# YTM32B1MC0 register map
Vendor: YTMicro; File version: 1.0
CPU: CM33 r0p4, little endian, MPU, FPU, 2 interrupt priority bits
Registers are 32-bit, read-write, reset 0x0 unless marked. A register's access mark holds for its fields unless they carry their own. Offsets are from the block's base; [hi:lo] are bit positions; {n}, {i} and the like mark numbered series; 'fields as' and 'values as' point back to an identical list.

## HCU — Hardware Cryptography Unit
Base 0x40067000; register names take the prefix HCU_
0x00 GO
  [0] GO — Start Encryption/Decryption and indicate the module work state, write 0 to this bit is invalid.
    0=Encryption/Decryption idle; 1=Encryption/Decryption running
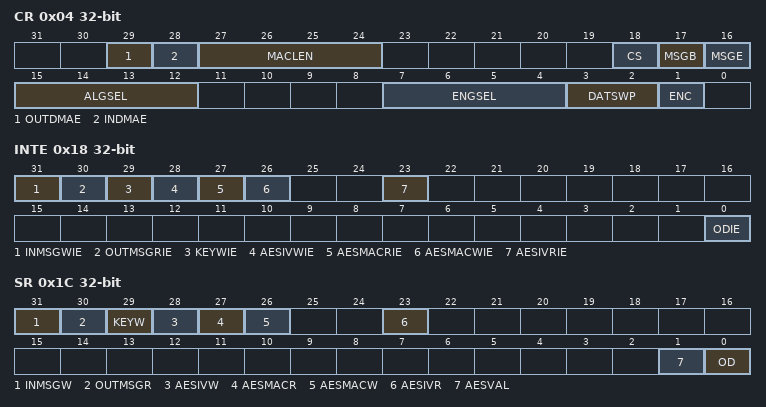
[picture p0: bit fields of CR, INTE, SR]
0x04 CR
  [29] OUTDMAE — Output message DMA enable/disable.
    0=Output message DMA is disabled; 1=Output message DMA is enabled
  [28] INDMAE — Input message DMA enable/disable.
    0=Input message dma is disabled; 1=Input message dma is enabled
  [27:24] MACLEN — MAC length for generation or validation.
    0=16 bytes; 1=1 byte; {v}={v} bytes (v=2..15)
  [18] CS — Store the context data, for multiple message blocks process.
    0=Don't store context data; 1=Store context data
  [17] MSGB — Indicate the first message block, for multiple message blocks process.
    0=Current data block isn't the first block of the whole data; 1=Current data block is the first block of the whole data
  [16] MSGE — Indicate the last message block, for multiple message blocks process.
    0=Current data block isn't the last block of the whole data; 1=Current data block is the last block of the whole data
  [15:12] ALGSEL — Select algorithm for selected engine.
    0=AES-ECB; 1=AES-CBC; 4=AES-CMAC
  [7:4] ENGSEL — Select engine for encryption/decryption.
    0=disable; 1=AES
  [3:2] DATSWP — Select the type of data swapping.
    0=No swapping; 1=Half-word swapping; 2=Byte swapping; 3=Bit swapping
  [1] ENC — Select encryption or decryption mode.
    0=Decryption; 1=Encryption
0x0C MSGCUR
  [15:0] MSGLEN — Indicate byte number of message in current block.
0x18 INTE
  [31] INMSGWIE — Input message wait interrupt enable/disable.
    0=Input message wait interrupt disable; 1=Input message wait interrupt enable
  [30] OUTMSGRIE — Output message ready interrupt enable/disable.
    0=Output message ready interrupt disable; 1=Output message ready interrupt enable
  [29] KEYWIE — Key wait interrupt enable/disable.
    0=Key wait interrupt disable; 1=Key wait interrupt enable
  [28] AESIVWIE — AES initial vector wait interrupt enable/disable.
    0=AES initial vector wait interrupt disable; 1=AES initial vector wait interrupt enable
  [27] AESMACRIE — AES MAC ready interrupt enable/disable.
    0=AES MAC ready interrupt disable; 1=AES MAC ready interrupt enable
  [26] AESMACWIE — AES MAC wait interrupt enable/disable.
    0=AES MAC wait interrupt disable; 1=AES MAC wait interrupt enable
  [23] AESIVRIE — AES initial vector ready interrupt enable/disable.
    0=AES initial vector ready interrupt disable; 1=AES initial vector ready interrupt enable
  [0] ODIE — Operation done interrupt enable/disable.
    0=Operation done interrupt disable; 1=Operation done interrupt enable
0x1C SR
  [31] INMSGW ro — Input message wait flag.
    0=Don't care; 1=HCU is waiting for input message. Need write INMSG register.
  [30] OUTMSGR ro — Output message ready flag.
    0=Don't care; 1=Output message is ready for reading. Need read OUTMSG register.
  [29] KEYW ro — Key wait flag.
    0=Don't care; 1=HCU is waiting for key. Need write KEY registers or execute load key value EFM command.
  [28] AESIVW ro — AES initial vector wait flag.
    0=Don't care; 1=HCU is waiting for AES initial vector. Need write CONTEXT_4_7 registers.
  [27] AESMACR ro — AES MAC ready flag.
    0=Don't care; 1=AES MAC is ready for reading. Need read CONTEXT_8_11 registers.
  [26] AESMACW ro — AES MAC wait flag.
    0=Don't care; 1=HCU is waiting for AES MAC. Need write CONTEXT_8_11 registers.
  [23] AESIVR ro — AES initial vector ready flag.
    0=Don't care; 1=AES initial vector is ready for reading. Need read CONTEXT_4_7 registers.
  [1] AESVAL ro — Indicate AES MAC validation result.
    0=The input MAC is not equal to the calculate result; 1=The input MAC is equal to the calculate result
  [0] OD — Indicate Encryption/Decryption operation state. Write 1 to clear this bit.
    0=Operation doesn't begin or under running; 1=Operation done
{0x20+4i} KEY{i} wo (i=0..3)
  [31:0] KEY rw — Key value for Encryption/Decryption.
0x60 CONTEXT_4_70
  [31:0] CONTEXT — Initial vector value for AES Encryption/Decryption.
0x64 CONTEXT_4_71
  [31:0] CONTEXT — Initial vector value for AES Encryption/Decryption.
0x68 CONTEXT_4_72
  [31:0] CONTEXT — Initial vector value for AES Encryption/Decryption.
0x6C CONTEXT_4_73
  [31:0] CONTEXT — Initial vector value for AES Encryption/Decryption.
0x70 CONTEXT_8_110
  [31:0] CONTEXT — MAC value generated in AES Encryption or write for AES Decryption.
0x74 CONTEXT_8_111
  fields as CONTEXT_8_110
0x78 CONTEXT_8_112
  fields as CONTEXT_8_110
0x7C CONTEXT_8_113
  fields as CONTEXT_8_110
0xB0 INMSG wo
  [31:0] INMSG rw — Input message, write data that to be encrypted/decrypted.
0xB4 OUTMSG ro
  [31:0] OUTMSG rw — Output message, read data that after encryption/decryption.
